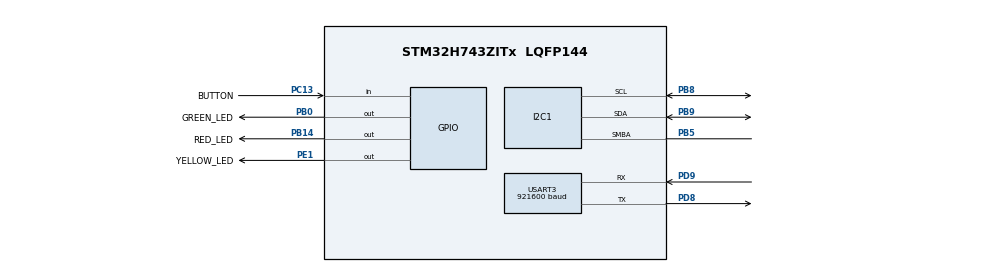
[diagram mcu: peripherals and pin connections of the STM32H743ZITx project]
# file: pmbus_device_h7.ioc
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CORTEX_M7.default_mode_Activation=1
FREERTOS.Tasks01=start,24,256,system_start,Default,NULL,Dynamic,NULL,NULL
FREERTOS.configGENERATE_RUN_TIME_STATS=1
FREERTOS.configRECORD_STACK_HIGH_ADDRESS=1
FREERTOS.configUSE_APPLICATION_TASK_TAG=1
FREERTOS.configUSE_STATS_FORMATTING_FUNCTIONS=1
I2C1.SMBusOwnAddress=smbus_slave_addr()
I2C1.SMBusPacketErrorCheckMode=SMBUS_PEC_ENABLE
I2C1.Timeout=0x000085B8
I2C1.Timing=0x307075B1
Mcu.Family=STM32H7
Mcu.Name=STM32H743ZITx
Mcu.Package=LQFP144
NVIC.I2C1_ER_IRQn=true\:5\:0\:false\:false\:true\:true\:true\:false\:true
NVIC.I2C1_EV_IRQn=true\:5\:0\:false\:false\:true\:true\:true\:false\:true
NVIC.PriorityGroup=NVIC_PRIORITYGROUP_4
PB0.GPIO_Label=GREEN_LED
PB0.PinState=GPIO_PIN_RESET
PB0.Signal=GPIO_Output
PB14.GPIO_Label=RED_LED
PB14.PinState=GPIO_PIN_RESET
PB14.Signal=GPIO_Output
PB5.Mode=SMBus-Alert-mode
PB5.Signal=I2C1_SMBA
PB8.GPIO_Pu=GPIO_PULLUP
PB8.GPIO_Speed=GPIO_SPEED_FREQ_VERY_HIGH
PB8.Mode=SMBus-Alert-mode
PB8.Signal=I2C1_SCL
PB9.GPIO_Pu=GPIO_PULLUP
PB9.GPIO_Speed=GPIO_SPEED_FREQ_VERY_HIGH
PB9.Mode=SMBus-Alert-mode
PB9.Signal=I2C1_SDA
PC13.GPIO_Label=BUTTON
PC13.Signal=GPIO_Input
PD8.Mode=Asynchronous
PD8.Signal=USART3_TX
PD9.Mode=Asynchronous
PD9.Signal=USART3_RX
PE1.GPIO_Label=YELLOW_LED
PE1.PinState=GPIO_PIN_RESET
PE1.Signal=GPIO_Output
PH0-OSC_IN\ (PH0).Mode=HSE-External-Clock-Source
PH0-OSC_IN\ (PH0).Signal=RCC_OSC_IN
ProjectManager.HeapSize=0x2000
ProjectManager.StackSize=0x1000
ProjectManager.TargetToolchain=CMake
RCC.ADCFreq_Value=16125000
RCC.APB1Freq_Value=120000000
RCC.APB2Freq_Value=120000000
RCC.APB3Freq_Value=120000000
RCC.APB4Freq_Value=120000000
RCC.CortexFreq_Value=480000000
RCC.D1PPRE=RCC_APB3_DIV2
RCC.D2PPRE1=RCC_APB1_DIV2
RCC.D2PPRE2=RCC_APB2_DIV2
RCC.D3PPRE=RCC_APB4_DIV2
RCC.DIVM1=1
RCC.DIVN1=120
RCC.HCLKFreq_Value=240000000
RCC.HPRE=RCC_HCLK_DIV2
RCC.HSE_VALUE=8000000
RCC.PLLFRACN=0
RCC.PLLSourceVirtual=RCC_PLLSOURCE_HSE
RCC.SYSCLKFreq_VALUE=480000000
RCC.SYSCLKSource=RCC_SYSCLKSOURCE_PLLCLK
RCC.USBFreq_Value=480000000
USART3.BaudRate=921600
USART3.VirtualMode-Asynchronous=VM_ASYNC
VP_FREERTOS_VS_CMSIS_V2.Mode=CMSIS_V2
VP_MEMORYMAP_VS_MEMORYMAP.Mode=CurAppReg
board=custom

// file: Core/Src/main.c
/* USER CODE BEGIN Header */
/**
  ******************************************************************************
  * @file           : main.c
  * @brief          : Main program body
  ******************************************************************************
  * @attention
  *
  * Copyright (c) 2025 STMicroelectronics.
  * All rights reserved.
  *
  * This software is licensed under terms that can be found in the LICENSE file
  * in the root directory of this software component.
  * If no LICENSE file comes with this software, it is provided AS-IS.
  *
  ******************************************************************************
  */
/* USER CODE END Header */
#include "main.h"
#include "cmsis_os.h"
#include "i2c.h"
#include "memorymap.h"
#include "usart.h"
#include "gpio.h"

/* USER CODE BEGIN Includes */
#include "application.h"
/* USER CODE END Includes */

void SystemClock_Config(void);
static void MPU_Config(void);
void MX_FREERTOS_Init(void);

int main(void)
{

  /* MPU Configuration--------------------------------------------------------*/
  MPU_Config();

  /* MCU Configuration--------------------------------------------------------*/

  /* Reset of all peripherals, Initializes the Flash interface and the Systick. */
  HAL_Init();

  /* Configure the system clock */
  SystemClock_Config();

  /* Initialize all configured peripherals */
  MX_GPIO_Init();
  MX_I2C1_SMBUS_Init();
  MX_USART3_UART_Init();
  /* USER CODE BEGIN 2 */
  application_init();
  application();
  /* USER CODE END 2 */

  /* Init scheduler */
  osKernelInitialize();

  /* Call init function for freertos objects (in cmsis_os2.c) */
  MX_FREERTOS_Init();

  /* Start scheduler */
  osKernelStart();

  /* We should never get here as control is now taken by the scheduler */

  /* Infinite loop */
  while (1)
  {

  }
}

void SystemClock_Config(void)
{
  RCC_OscInitTypeDef RCC_OscInitStruct = {0};
  RCC_ClkInitTypeDef RCC_ClkInitStruct = {0};

  /** Supply configuration update enable
  */
  HAL_PWREx_ConfigSupply(PWR_LDO_SUPPLY);

  /** Configure the main internal regulator output voltage
  */
  __HAL_PWR_VOLTAGESCALING_CONFIG(PWR_REGULATOR_VOLTAGE_SCALE0);

  while(!__HAL_PWR_GET_FLAG(PWR_FLAG_VOSRDY)) {}

  /** Initializes the RCC Oscillators according to the specified parameters
  * in the RCC_OscInitTypeDef structure.
  */
  RCC_OscInitStruct.OscillatorType = RCC_OSCILLATORTYPE_HSE;
  RCC_OscInitStruct.HSEState = RCC_HSE_BYPASS;
  RCC_OscInitStruct.PLL.PLLState = RCC_PLL_ON;
  RCC_OscInitStruct.PLL.PLLSource = RCC_PLLSOURCE_HSE;
  RCC_OscInitStruct.PLL.PLLM = 1;
  RCC_OscInitStruct.PLL.PLLN = 120;
  RCC_OscInitStruct.PLL.PLLP = 2;
  RCC_OscInitStruct.PLL.PLLQ = 2;
  RCC_OscInitStruct.PLL.PLLR = 2;
  RCC_OscInitStruct.PLL.PLLRGE = RCC_PLL1VCIRANGE_3;
  RCC_OscInitStruct.PLL.PLLVCOSEL = RCC_PLL1VCOWIDE;
  RCC_OscInitStruct.PLL.PLLFRACN = 0;
  if (HAL_RCC_OscConfig(&RCC_OscInitStruct) != HAL_OK)
  {
    Error_Handler();
  }

  /** Initializes the CPU, AHB and APB buses clocks
  */
  RCC_ClkInitStruct.ClockType = RCC_CLOCKTYPE_HCLK|RCC_CLOCKTYPE_SYSCLK
                              |RCC_CLOCKTYPE_PCLK1|RCC_CLOCKTYPE_PCLK2
                              |RCC_CLOCKTYPE_D3PCLK1|RCC_CLOCKTYPE_D1PCLK1;
  RCC_ClkInitStruct.SYSCLKSource = RCC_SYSCLKSOURCE_PLLCLK;
  RCC_ClkInitStruct.SYSCLKDivider = RCC_SYSCLK_DIV1;
  RCC_ClkInitStruct.AHBCLKDivider = RCC_HCLK_DIV2;
  RCC_ClkInitStruct.APB3CLKDivider = RCC_APB3_DIV2;
  RCC_ClkInitStruct.APB1CLKDivider = RCC_APB1_DIV2;
  RCC_ClkInitStruct.APB2CLKDivider = RCC_APB2_DIV2;
  RCC_ClkInitStruct.APB4CLKDivider = RCC_APB4_DIV2;

  if (HAL_RCC_ClockConfig(&RCC_ClkInitStruct, FLASH_LATENCY_4) != HAL_OK)
  {
    Error_Handler();
  }
}

 /* MPU Configuration */

void MPU_Config(void)
{
  MPU_Region_InitTypeDef MPU_InitStruct = {0};

  /* Disables the MPU */
  HAL_MPU_Disable();

  /** Initializes and configures the Region and the memory to be protected
  */
  MPU_InitStruct.Enable = MPU_REGION_ENABLE;
  MPU_InitStruct.Number = MPU_REGION_NUMBER0;
  MPU_InitStruct.BaseAddress = 0x0;
  MPU_InitStruct.Size = MPU_REGION_SIZE_4GB;
  MPU_InitStruct.SubRegionDisable = 0x87;
  MPU_InitStruct.TypeExtField = MPU_TEX_LEVEL0;
  MPU_InitStruct.AccessPermission = MPU_REGION_NO_ACCESS;
  MPU_InitStruct.DisableExec = MPU_INSTRUCTION_ACCESS_DISABLE;
  MPU_InitStruct.IsShareable = MPU_ACCESS_SHAREABLE;
  MPU_InitStruct.IsCacheable = MPU_ACCESS_NOT_CACHEABLE;
  MPU_InitStruct.IsBufferable = MPU_ACCESS_NOT_BUFFERABLE;

  HAL_MPU_ConfigRegion(&MPU_InitStruct);
  /* Enables the MPU */
  HAL_MPU_Enable(MPU_PRIVILEGED_DEFAULT);

}

void Error_Handler(void)
{
  __disable_irq();
  while (1)
  {
  }
}

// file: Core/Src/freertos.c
/* USER CODE BEGIN Header */
/**
 ******************************************************************************
 * File Name          : freertos.c
 * Description        : Code for freertos applications
 ******************************************************************************
 * @attention
 *
 * Copyright (c) 2025 STMicroelectronics.
 * All rights reserved.
 *
 * This software is licensed under terms that can be found in the LICENSE file
 * in the root directory of this software component.
 * If no LICENSE file comes with this software, it is provided AS-IS.
 *
 ******************************************************************************
 */
/* USER CODE END Header */

#include "FreeRTOS.h"
#include "task.h"
#include "main.h"
#include "cmsis_os.h"

/* USER CODE BEGIN Includes */
#include "application.h"
/* USER CODE END Includes */

/* Definitions for start */
osThreadId_t startHandle;
const osThreadAttr_t start_attributes = {
  .name = "start",
  .stack_size = 256 * 4,
  .priority = (osPriority_t) osPriorityNormal,
};

void system_start(void *argument);

void MX_FREERTOS_Init(void); /* (MISRA C 2004 rule 8.1) */

/* Hook prototypes */
void configureTimerForRunTimeStats(void);
unsigned long getRunTimeCounterValue(void);

/* USER CODE BEGIN 1 */
/* Functions needed when configGENERATE_RUN_TIME_STATS is on */
__weak void configureTimerForRunTimeStats(void) {}

__weak unsigned long getRunTimeCounterValue(void) {
    return HAL_GetTick();
}
/* USER CODE END 1 */

void MX_FREERTOS_Init(void) {

  /* Create the thread(s) */
  /* creation of start */
  startHandle = osThreadNew(system_start, NULL, &start_attributes);

}

void system_start(void *argument)
{
  /* USER CODE BEGIN system_start */
    (void)argument;

    start_info();
    vTaskDelete(NULL);
  /* USER CODE END system_start */
}
